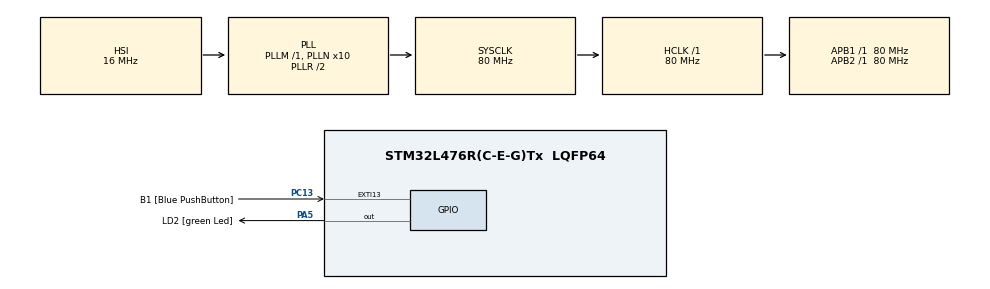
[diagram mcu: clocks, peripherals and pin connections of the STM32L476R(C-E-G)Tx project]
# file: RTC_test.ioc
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Mcu.Family=STM32L4
Mcu.Name=STM32L476R(C-E-G)Tx
Mcu.Package=LQFP64
NVIC.PriorityGroup=NVIC_PRIORITYGROUP_4
NVIC.RTC_Alarm_IRQn=true\:0\:0\:false\:false\:true
NVIC.RTC_WKUP_IRQn=true\:0\:0\:false\:false\:true
PA13.GPIO_Label=TMS
PA13.Signal=SYS_JTMS-SWDIO
PA14.GPIO_Label=TCK
PA14.Signal=SYS_JTCK-SWCLK
PA2.GPIO_Label=USART_TX
PA2.GPIO_Mode=GPIO_MODE_AF_PP
PA2.GPIO_PuPd=GPIO_NOPULL
PA2.GPIO_Speed=GPIO_SPEED_FREQ_VERY_HIGH
PA2.Signal=USART2_TX
PA3.GPIO_Label=USART_RX
PA3.GPIO_Mode=GPIO_MODE_AF_PP
PA3.GPIO_PuPd=GPIO_NOPULL
PA3.GPIO_Speed=GPIO_SPEED_FREQ_VERY_HIGH
PA3.Signal=USART2_RX
PA5.GPIO_Label=LD2 [green Led]
PA5.GPIO_ModeDefaultOutputPP=GPIO_MODE_OUTPUT_PP
PA5.GPIO_PuPd=GPIO_NOPULL
PA5.GPIO_Speed=GPIO_SPEED_FREQ_LOW
PA5.Signal=GPIO_Output
PB3.GPIO_Label=SWO
PB3.Signal=SYS_JTDO-SWO
PC13.GPIO_Label=B1 [Blue PushButton]
PC13.GPIO_ModeDefaultEXTI=GPIO_MODE_IT_FALLING
PC13.GPIO_PuPd=GPIO_NOPULL
PC13.Signal=GPXTI13
PC14/OSC32_IN.Signal=RCC_OSC32_IN
PC15/OSC32_OUT.Signal=RCC_OSC32_OUT
PH0/OSC_IN.Mode=HSE-External-Oscillator
PH0/OSC_IN.Signal=RCC_OSC_IN
PH1/OSC_OUT.Mode=HSE-External-Oscillator
PH1/OSC_OUT.Signal=RCC_OSC_OUT
ProjectManager.HeapSize=0x200
ProjectManager.StackSize=0x400
ProjectManager.TargetToolchain=EWARM
RCC.ADCFreq_Value=64000000
RCC.AHBFreq_Value=80000000
RCC.APB1Freq_Value=80000000
RCC.APB1TimFreq_Value=80000000
RCC.APB2Freq_Value=80000000
RCC.APB2TimFreq_Value=80000000
RCC.CortexFreq_Value=80000000
RCC.HCLKFreq_Value=80000000
RCC.HSE_VALUE=8000000
RCC.HSI_VALUE=16000000
RCC.LSE_VALUE=32768
RCC.MSI_VALUE=4000000
RCC.PLLN=10
RCC.PLLSourceVirtual=RCC_PLLSOURCE_HSI
RCC.PREFETCH_ENABLE=1
RCC.SYSCLKFreq_VALUE=80000000
RCC.SYSCLKSource=RCC_SYSCLKSOURCE_PLLCLK
RCC.USBFreq_Value=64000000
RCC.VCOOutputFreq_Value=160000000
RTC.Date=22
RTC.Hours=10
RTC.Minutes=15
RTC.Month=RTC_MONTH_MARCH
RTC.Seconds=15
RTC.Seconds_A-Alarm\ A=10
RTC.WeekDay=RTC_WEEKDAY_WEDNESDAY
RTC.Year=17
VP_RTC_VS_RTC_Activate.Mode=RTC_Enabled
VP_RTC_VS_RTC_Alarm_A_Intern.Mode=Alarm A
VP_RTC_VS_RTC_Calendar.Mode=RTC_Calendar
VP_RTC_VS_RTC_WakeUp_intern.Mode=WakeUp
board=NUCLEO-L476RG

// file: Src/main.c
/**
  ******************************************************************************
  * File Name          : main.c
  * Description        : Main program body
  ******************************************************************************
  *
  * COPYRIGHT(c) 2017 STMicroelectronics
  *
  * Redistribution and use in source and binary forms, with or without modification,
  * are permitted provided that the following conditions are met:
  *   1. Redistributions of source code must retain the above copyright notice,
  *      this list of conditions and the following disclaimer.
  *   2. Redistributions in binary form must reproduce the above copyright notice,
  *      this list of conditions and the following disclaimer in the documentation
  *      and/or other materials provided with the distribution.
  *   3. Neither the name of STMicroelectronics nor the names of its contributors
  *      may be used to endorse or promote products derived from this software
  *      without specific prior written permission.
  *
  * THIS SOFTWARE IS PROVIDED BY THE COPYRIGHT HOLDERS AND CONTRIBUTORS "AS IS"
  * AND ANY EXPRESS OR IMPLIED WARRANTIES, INCLUDING, BUT NOT LIMITED TO, THE
  * IMPLIED WARRANTIES OF MERCHANTABILITY AND FITNESS FOR A PARTICULAR PURPOSE ARE
  * DISCLAIMED. IN NO EVENT SHALL THE COPYRIGHT HOLDER OR CONTRIBUTORS BE LIABLE
  * FOR ANY DIRECT, INDIRECT, INCIDENTAL, SPECIAL, EXEMPLARY, OR CONSEQUENTIAL
  * DAMAGES (INCLUDING, BUT NOT LIMITED TO, PROCUREMENT OF SUBSTITUTE GOODS OR
  * SERVICES; LOSS OF USE, DATA, OR PROFITS; OR BUSINESS INTERRUPTION) HOWEVER
  * CAUSED AND ON ANY THEORY OF LIABILITY, WHETHER IN CONTRACT, STRICT LIABILITY,
  * OR TORT (INCLUDING NEGLIGENCE OR OTHERWISE) ARISING IN ANY WAY OUT OF THE USE
  * OF THIS SOFTWARE, EVEN IF ADVISED OF THE POSSIBILITY OF SUCH DAMAGE.
  *
  ******************************************************************************
  */
#include "main.h"
#include "stm32l4xx_hal.h"

RTC_HandleTypeDef hrtc;

/* USER CODE BEGIN PV */
/* Private variables ---------------------------------------------------------*/

/* USER CODE END PV */

void SystemClock_Config(void);
void Error_Handler(void);
static void MX_GPIO_Init(void);
static void MX_RTC_Init(void);

/* USER CODE BEGIN PFP */
/* Private function prototypes -----------------------------------------------*/

/* USER CODE END PFP */

/* USER CODE BEGIN 0 */
uint8_t Hour;
uint8_t Min;
uint8_t Sec;

uint8_t counter=0;

void HAL_RTC_AlarmAEventCallback (RTC_HandleTypeDef *hrtc){

  counter += 100;
}
/* USER CODE END 0 */

int main(void)
{

  /* MCU Configuration----------------------------------------------------------*/

  /* Reset of all peripherals, Initializes the Flash interface and the Systick. */
  HAL_Init();

  /* Configure the system clock */
  SystemClock_Config();

  /* Initialize all configured peripherals */
  MX_GPIO_Init();
  MX_RTC_Init();

  /* USER CODE BEGIN 2 */
  RTC_TimeTypeDef RTC_Time;
  RTC_AlarmTypeDef RTC_Alarm_Time;
  RTC_DateTypeDef RTC Date;

  HAL_RTC_GetTime (&hrtc, &RTC_Time, RTC_FORMAT_BCD);
  Hour = RTC_Time.Hours;
  Min = RTC_Time.Minutes;
  Sec = RTC_Time.Seconds;

  RTC_Time.Hours=0x05;
  RTC_Time.Minutes=0x05;
  RTC_Time.Seconds=0x00;

  RTC_Alarm_Time.Alarm=1;
  RTC_Alarm_Time.AlarmTime.Hours = 0x05;
  RTC_Alarm_Time.AlarmTime.Minutes = 0x05;
  RTC_Alarm_Time.AlarmTime.Seconds = 0x30;

  HAL_Delay(5000);
  HAL_RTC_SetTime (&hrtc, &RTC_Time, RTC_FORMAT_BCD);
  HAL_RTC_SetAlarm_IT(&hrtc, &RTC_Alarm_Time, RTC_FORMAT_BCD);

  /* USER CODE END 2 */

  /* Infinite loop */
  while (1)
  {
  HAL_RTC_GetTime (&hrtc, &RTC_Time, RTC_FORMAT_BCD);
  Hour = RTC_Time.Hours;
  Min = RTC_Time.Minutes;
  Sec = RTC_Time.Seconds;
  }

}

/** System Clock Configuration
*/
void SystemClock_Config(void)
{

  RCC_OscInitTypeDef RCC_OscInitStruct;
  RCC_ClkInitTypeDef RCC_ClkInitStruct;
  RCC_PeriphCLKInitTypeDef PeriphClkInit;

    /**Initializes the CPU, AHB and APB busses clocks
    */
  RCC_OscInitStruct.OscillatorType = RCC_OSCILLATORTYPE_HSI|RCC_OSCILLATORTYPE_LSI;
  RCC_OscInitStruct.HSIState = RCC_HSI_ON;
  RCC_OscInitStruct.HSICalibrationValue = 16;
  RCC_OscInitStruct.LSIState = RCC_LSI_ON;
  RCC_OscInitStruct.PLL.PLLState = RCC_PLL_ON;
  RCC_OscInitStruct.PLL.PLLSource = RCC_PLLSOURCE_HSI;
  RCC_OscInitStruct.PLL.PLLM = 1;
  RCC_OscInitStruct.PLL.PLLN = 10;
  RCC_OscInitStruct.PLL.PLLP = RCC_PLLP_DIV7;
  RCC_OscInitStruct.PLL.PLLQ = RCC_PLLQ_DIV2;
  RCC_OscInitStruct.PLL.PLLR = RCC_PLLR_DIV2;
  if (HAL_RCC_OscConfig(&RCC_OscInitStruct) != HAL_OK)
  {
    Error_Handler();
  }

    /**Initializes the CPU, AHB and APB busses clocks
    */
  RCC_ClkInitStruct.ClockType = RCC_CLOCKTYPE_HCLK|RCC_CLOCKTYPE_SYSCLK
                              |RCC_CLOCKTYPE_PCLK1|RCC_CLOCKTYPE_PCLK2;
  RCC_ClkInitStruct.SYSCLKSource = RCC_SYSCLKSOURCE_PLLCLK;
  RCC_ClkInitStruct.AHBCLKDivider = RCC_SYSCLK_DIV1;
  RCC_ClkInitStruct.APB1CLKDivider = RCC_HCLK_DIV1;
  RCC_ClkInitStruct.APB2CLKDivider = RCC_HCLK_DIV1;

  if (HAL_RCC_ClockConfig(&RCC_ClkInitStruct, FLASH_LATENCY_4) != HAL_OK)
  {
    Error_Handler();
  }

  PeriphClkInit.PeriphClockSelection = RCC_PERIPHCLK_RTC;
  PeriphClkInit.RTCClockSelection = RCC_RTCCLKSOURCE_LSI;
  if (HAL_RCCEx_PeriphCLKConfig(&PeriphClkInit) != HAL_OK)
  {
    Error_Handler();
  }

    /**Configure the main internal regulator output voltage
    */
  if (HAL_PWREx_ControlVoltageScaling(PWR_REGULATOR_VOLTAGE_SCALE1) != HAL_OK)
  {
    Error_Handler();
  }

    /**Configure the Systick interrupt time
    */
  HAL_SYSTICK_Config(HAL_RCC_GetHCLKFreq()/1000);

    /**Configure the Systick
    */
  HAL_SYSTICK_CLKSourceConfig(SYSTICK_CLKSOURCE_HCLK);

  /* SysTick_IRQn interrupt configuration */
  HAL_NVIC_SetPriority(SysTick_IRQn, 0, 0);
}

/* RTC init function */
static void MX_RTC_Init(void)
{

  RTC_TimeTypeDef sTime;
  RTC_DateTypeDef sDate;
  RTC_AlarmTypeDef sAlarm;

    /**Initialize RTC Only
    */
  hrtc.Instance = RTC;
  hrtc.Init.HourFormat = RTC_HOURFORMAT_24;
  hrtc.Init.AsynchPrediv = 127;
  hrtc.Init.SynchPrediv = 255;
  hrtc.Init.OutPut = RTC_OUTPUT_DISABLE;
  hrtc.Init.OutPutRemap = RTC_OUTPUT_REMAP_NONE;
  hrtc.Init.OutPutPolarity = RTC_OUTPUT_POLARITY_HIGH;
  hrtc.Init.OutPutType = RTC_OUTPUT_TYPE_OPENDRAIN;
  if (HAL_RTC_Init(&hrtc) != HAL_OK)
  {
    Error_Handler();
  }

    /**Initialize RTC and set the Time and Date
    */
  sTime.Hours = 0x10;
  sTime.Minutes = 0x15;
  sTime.Seconds = 0x15;
  sTime.DayLightSaving = RTC_DAYLIGHTSAVING_NONE;
  sTime.StoreOperation = RTC_STOREOPERATION_RESET;
  if (HAL_RTC_SetTime(&hrtc, &sTime, RTC_FORMAT_BCD) != HAL_OK)
  {
    Error_Handler();
  }

  sDate.WeekDay = RTC_WEEKDAY_WEDNESDAY;
  sDate.Month = RTC_MONTH_MARCH;
  sDate.Date = 0x22;
  sDate.Year = 0x17;

  if (HAL_RTC_SetDate(&hrtc, &sDate, RTC_FORMAT_BCD) != HAL_OK)
  {
    Error_Handler();
  }

    /**Enable the Alarm A
    */
  sAlarm.AlarmTime.Hours = 0x0;
  sAlarm.AlarmTime.Minutes = 0x0;
  sAlarm.AlarmTime.Seconds = 0x10;
  sAlarm.AlarmTime.SubSeconds = 0x0;
  sAlarm.AlarmTime.DayLightSaving = RTC_DAYLIGHTSAVING_NONE;
  sAlarm.AlarmTime.StoreOperation = RTC_STOREOPERATION_RESET;
  sAlarm.AlarmMask = RTC_ALARMMASK_NONE;
  sAlarm.AlarmSubSecondMask = RTC_ALARMSUBSECONDMASK_ALL;
  sAlarm.AlarmDateWeekDaySel = RTC_ALARMDATEWEEKDAYSEL_DATE;
  sAlarm.AlarmDateWeekDay = 0x1;
  sAlarm.Alarm = RTC_ALARM_A;
  if (HAL_RTC_SetAlarm_IT(&hrtc, &sAlarm, RTC_FORMAT_BCD) != HAL_OK)
  {
    Error_Handler();
  }

    /**Enable the WakeUp
    */
  if (HAL_RTCEx_SetWakeUpTimer_IT(&hrtc, 0, RTC_WAKEUPCLOCK_RTCCLK_DIV16) != HAL_OK)
  {
    Error_Handler();
  }

}

/** Configure pins as
        * Analog
        * Input
        * Output
        * EVENT_OUT
        * EXTI
     PA2   ------> USART2_TX
     PA3   ------> USART2_RX
*/
static void MX_GPIO_Init(void)
{

  GPIO_InitTypeDef GPIO_InitStruct;

  /* GPIO Ports Clock Enable */
  __HAL_RCC_GPIOC_CLK_ENABLE();
  __HAL_RCC_GPIOH_CLK_ENABLE();
  __HAL_RCC_GPIOA_CLK_ENABLE();
  __HAL_RCC_GPIOB_CLK_ENABLE();

  /*Configure GPIO pin Output Level */
  HAL_GPIO_WritePin(LD2_GPIO_Port, LD2_Pin, GPIO_PIN_RESET);

  /*Configure GPIO pin : B1_Pin */
  GPIO_InitStruct.Pin = B1_Pin;
  GPIO_InitStruct.Mode = GPIO_MODE_IT_FALLING;
  GPIO_InitStruct.Pull = GPIO_NOPULL;
  HAL_GPIO_Init(B1_GPIO_Port, &GPIO_InitStruct);

  /*Configure GPIO pins : USART_TX_Pin USART_RX_Pin */
  GPIO_InitStruct.Pin = USART_TX_Pin|USART_RX_Pin;
  GPIO_InitStruct.Mode = GPIO_MODE_AF_PP;
  GPIO_InitStruct.Pull = GPIO_NOPULL;
  GPIO_InitStruct.Speed = GPIO_SPEED_FREQ_VERY_HIGH;
  GPIO_InitStruct.Alternate = GPIO_AF7_USART2;
  HAL_GPIO_Init(GPIOA, &GPIO_InitStruct);

  /*Configure GPIO pin : LD2_Pin */
  GPIO_InitStruct.Pin = LD2_Pin;
  GPIO_InitStruct.Mode = GPIO_MODE_OUTPUT_PP;
  GPIO_InitStruct.Pull = GPIO_NOPULL;
  GPIO_InitStruct.Speed = GPIO_SPEED_FREQ_LOW;
  HAL_GPIO_Init(LD2_GPIO_Port, &GPIO_InitStruct);

}

void Error_Handler(void)
{
  while(1)
  {
  }
}

/************************ (C) COPYRIGHT STMicroelectronics *****END OF FILE****/
